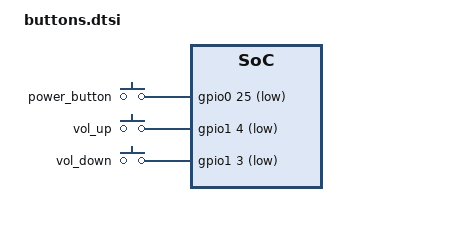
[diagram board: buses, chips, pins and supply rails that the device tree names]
/* Copyright 2026 The ChromiumOS Authors
 * Use of this source code is governed by a BSD-style license that can be
 * found in the LICENSE file.
 */

#include <zephyr/dt-bindings/input/input-event-codes.h>

/ {
	cros_buttons: buttons {
		compatible = "gpio-keys";
		zephyr,suspend-action = "none";

		power_button: pwrbtn-ec-in-n {
			gpios = <&gpio0 25 GPIO_ACTIVE_LOW>;
			zephyr,code = <INPUT_KEY_POWER>;
		};

		vol_up: vol-up-ec {
			gpios = <&gpio1 4 GPIO_ACTIVE_LOW>;
			zephyr,code = <INPUT_KEY_VOLUMEUP>;
		};

		vol_down: vol-down-ec {
			gpios = <&gpio1 3 GPIO_ACTIVE_LOW>;
			zephyr,code = <INPUT_KEY_VOLUMEDOWN>;
		};
	};
};

/* Remove legacy GPIO definitions since they're now part of cros_buttons */
&gpio_ec_pwr_btn_odl {
	/delete-property/ enum-name;
};

&gpio_ec_volup_btn_odl {
	/delete-property/ enum-name;
};

&gpio_ec_voldn_btn_odl {
	/delete-property/ enum-name;
};
